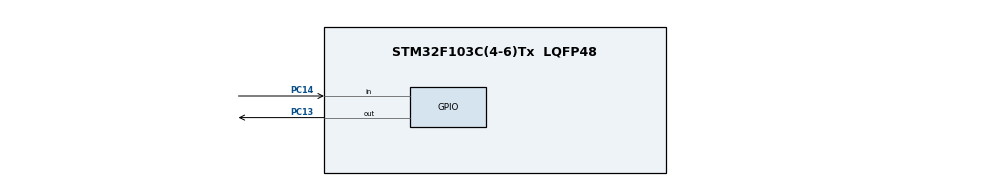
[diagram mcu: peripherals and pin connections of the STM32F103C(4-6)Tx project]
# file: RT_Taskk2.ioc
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Mcu.Family=STM32F1
Mcu.Name=STM32F103C(4-6)Tx
Mcu.Package=LQFP48
NVIC.PriorityGroup=NVIC_PRIORITYGROUP_4
PC13-TAMPER-RTC.Signal=GPIO_Output
PC14-OSC32_IN.Signal=GPIO_Input
ProjectManager.HeapSize=0x200
ProjectManager.StackSize=0x400
ProjectManager.TargetToolchain=STM32CubeIDE
RCC.APB1Freq_Value=8000000
RCC.APB2Freq_Value=8000000
board=custom

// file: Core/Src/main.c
/* USER CODE BEGIN Header */
/**
  ******************************************************************************
  * @file           : main.c
  * @brief          : Button-controlled LED with debounce
  ******************************************************************************
  * @attention
  *
  * Copyright (c) 2025 STMicroelectronics.
  * All rights reserved.
  *
  * This software is licensed under terms that can be found in the LICENSE file
  * in the root directory of this software component.
  * If no LICENSE file comes with this software, it is provided AS-IS.
  *
  ******************************************************************************
  */
/* USER CODE END Header */

#include "main.h"

/* USER CODE BEGIN Includes */
#define LED_GPIO_PORT    GPIOC
#define LED_PIN          GPIO_PIN_13
#define BUTTON_GPIO_PORT GPIOC
#define BUTTON_PIN       GPIO_PIN_14
/* USER CODE END Includes */

/* USER CODE BEGIN PV */
uint32_t debounceDelay = 50; // 50 ms debounce
/* USER CODE END PV */

void SystemClock_Config(void);
static void MX_GPIO_Init(void);

int main(void)
{
  /* MCU Configuration--------------------------------------------------------*/
  HAL_Init();  //Page #47
  SystemClock_Config();
  MX_GPIO_Init();

  /* Infinite loop */
  while (1)
  {
      // If button pressed (active-low)
	  // Page #227
      if (HAL_GPIO_ReadPin(BUTTON_GPIO_PORT, BUTTON_PIN) == GPIO_PIN_RESET)
      {
          //Page #228
    	  HAL_GPIO_TogglePin(LED_GPIO_PORT, LED_PIN); // toggle LED

          // Wait until button is released Page # 227
          while (HAL_GPIO_ReadPin(BUTTON_GPIO_PORT, BUTTON_PIN) == GPIO_PIN_RESET);
          //Page #50
          HAL_Delay(debounceDelay); // small delay for debouncing
      }
  }
}

void SystemClock_Config(void)
{
  RCC_OscInitTypeDef RCC_OscInitStruct = {0};
  RCC_ClkInitTypeDef RCC_ClkInitStruct = {0};

  RCC_OscInitStruct.OscillatorType = RCC_OSCILLATORTYPE_HSI;
  RCC_OscInitStruct.HSIState = RCC_HSI_ON;
  RCC_OscInitStruct.HSICalibrationValue = RCC_HSICALIBRATION_DEFAULT;
  RCC_OscInitStruct.PLL.PLLState = RCC_PLL_NONE;
  if (HAL_RCC_OscConfig(&RCC_OscInitStruct) != HAL_OK) { Error_Handler(); }

  RCC_ClkInitStruct.ClockType = RCC_CLOCKTYPE_HCLK|RCC_CLOCKTYPE_SYSCLK
                              |RCC_CLOCKTYPE_PCLK1|RCC_CLOCKTYPE_PCLK2;
  RCC_ClkInitStruct.SYSCLKSource = RCC_SYSCLKSOURCE_HSI;
  RCC_ClkInitStruct.AHBCLKDivider = RCC_SYSCLK_DIV1;
  RCC_ClkInitStruct.APB1CLKDivider = RCC_HCLK_DIV1;
  RCC_ClkInitStruct.APB2CLKDivider = RCC_HCLK_DIV1;
  if (HAL_RCC_ClockConfig(&RCC_ClkInitStruct, FLASH_LATENCY_0) != HAL_OK) { Error_Handler(); }
}

static void MX_GPIO_Init(void)
{
  GPIO_InitTypeDef GPIO_InitStruct = {0};

  /* GPIO Ports Clock Enable */
  __HAL_RCC_GPIOC_CLK_ENABLE();

  /*Configure GPIO pin Output Level for LED */
  HAL_GPIO_WritePin(LED_GPIO_PORT, LED_PIN, GPIO_PIN_RESET);

  /*Configure GPIO pin : LED */
  GPIO_InitStruct.Pin = LED_PIN;
  GPIO_InitStruct.Mode = GPIO_MODE_OUTPUT_PP;
  GPIO_InitStruct.Pull = GPIO_NOPULL;
  GPIO_InitStruct.Speed = GPIO_SPEED_FREQ_LOW;
  HAL_GPIO_Init(LED_GPIO_PORT, &GPIO_InitStruct);

  /*Configure GPIO pin : Button (PC14) */
  GPIO_InitStruct.Pin = BUTTON_PIN;
  GPIO_InitStruct.Mode = GPIO_MODE_INPUT;
  GPIO_InitStruct.Pull = GPIO_PULLUP; // Use internal pull-up
  HAL_GPIO_Init(BUTTON_GPIO_PORT, &GPIO_InitStruct);
}

void Error_Handler(void)
{
  __disable_irq();
  while (1) { }
}
